# R7FA4W1AD register map
Vendor: Renesas; Series: RA4; File version: 1.0
CPU: CM4 r0p1, little endian, MPU, FPU, VTOR, 4 interrupt priority bits
Registers are 8-bit, read-write, reset 0x0 unless marked. A register's access mark holds for its fields unless they carry their own. Offsets are from the block's base; [hi:lo] are bit positions; {n}, {i} and the like mark numbered series.

## RTC — Realtime Clock
Base 0x40044000
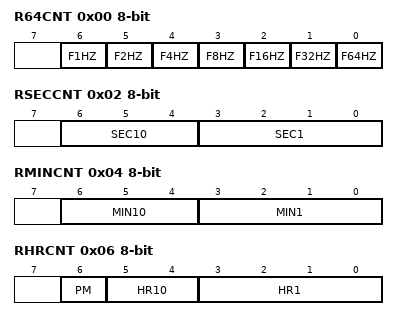
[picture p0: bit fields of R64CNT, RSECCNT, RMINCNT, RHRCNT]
0x00 R64CNT ro (reset mask 0x80) — 64-Hz Counter
  [6] F1HZ — 1Hz
  [5] F2HZ — 2Hz
  [4] F4HZ — 4Hz
  [3] F8HZ — 8Hz
  [2] F16HZ — 16Hz
  [1] F32HZ — 32Hz
  [0] F64HZ — 64Hz
0x02 RSECCNT reset not defined — Second Counter
  [6:4] SEC10 — 10-Second Count Counts from 0 to 5 for 60-second counting.
  [3:0] SEC1 — 1-Second Count Counts from 0 to 9 every second. When a carry is generated, 1 is added to the tens place.
0x02 BCNT0 reset not defined (alternate view of RSECCNT) — Binary Counter 0
  [7:0] BCNT0 — The BCNT0 counter is a readable/writable 32-bit binary counter b7 to b0.
0x04 RMINCNT reset not defined — Minute Counter
  [6:4] MIN10 — 10-Minute Count Counts from 0 to 5 for 60-minute counting.
  [3:0] MIN1 — 1-Minute Count Counts from 0 to 9 every minute. When a carry is generated, 1 is added to the tens place.
0x04 BCNT1 reset not defined (alternate view of RMINCNT) — Binary Counter 1
  [7:0] BCNT1 — The BCNT1 counter is a readable/writable 32-bit binary counter b15 to b8.
0x06 RHRCNT reset not defined — Hour Counter
  [6] PM — Time Counter Setting for a.m./p.m.
  [5:4] HR10 — 10-Hour Count Counts from 0 to 2 once per carry from the ones place.
  [3:0] HR1 — 1-Hour Count Counts from 0 to 9 once per hour. When a carry is generated, 1 is added to the tens place.
0x06 BCNT2 reset not defined (alternate view of RHRCNT) — Binary Counter 2
  [7:0] BCNT2 — The BCNT2 counter is a readable/writable 32-bit binary counter b23 to b16.
0x08 RWKCNT reset not defined — Day,of,Week Counter
  [2:0] DAYW — Day,of,Week Counting
0x08 BCNT3 reset not defined (alternate view of RWKCNT) — Binary Counter 3
  [7:0] BCNT3 — The BCNT3 counter is a readable/writable 32-bit binary counter b31 to b24.
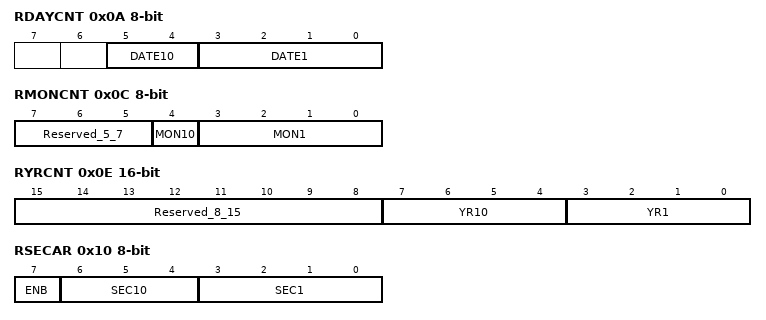
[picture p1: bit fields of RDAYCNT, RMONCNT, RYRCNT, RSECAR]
0x0A RDAYCNT (reset mask 0xC0) — Day Counter
  [5:4] DATE10 — 10-Day Count Counts from 0 to 3 once per carry from the ones place.
  [3:0] DATE1 — 1-Day Count Counts from 0 to 9 once per day. When a carry is generated, 1 is added to the tens place.
0x0C RMONCNT (reset mask 0xE0) — Month Counter
  [7:5] Reserved_5_7 — These bits are read as 000. The write value should be 000.
  [4] MON10 — 10-Month Count Counts from 0 to 1 once per carry from the ones place.
  [3:0] MON1 — 1-Month Count Counts from 0 to 9 once per month. When a carry is generated, 1 is added to the tens place.
0x0E RYRCNT 16-bit (reset mask 0xFF00) — Year Counter
  [15:8] Reserved_8_15 — These bits are read as 00000000. The write value should be 00000000.
  [7:4] YR10 — 10-Year Count Counts from 0 to 9 once per carry from ones place. When a carry is generated in the tens place, 1 is added to the hundreds place.
  [3:0] YR1 — 1-Year Count Counts from 0 to 9 once per year. When a carry is generated, 1 is added to the tens place.
0x10 RSECAR reset not defined — Second Alarm Register
  [7] ENB — Compare enable
  [6:4] SEC10 — 10-Seconds Value for the tens place of seconds
  [3:0] SEC1 wo — 1-Second Value for the ones place of seconds
0x10 BCNT0AR reset not defined (alternate view of RSECAR) — Binary Counter 0 Alarm Register
  [7:0] BCNT0AR — he BCNT0AR counter is a readable/writable alarm register corresponding to 32-bit binary counter b7 to b0.
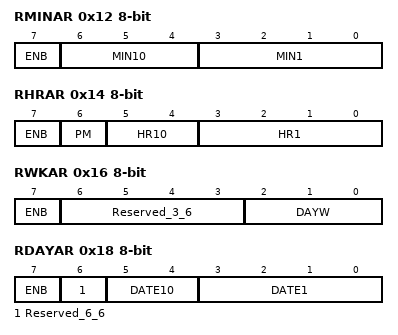
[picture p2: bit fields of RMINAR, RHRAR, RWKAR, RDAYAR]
0x12 RMINAR reset not defined — Minute Alarm Register
  [7] ENB — Compare enable
  [6:4] MIN10 — 10-Minute Count Value for the tens place of minutes
  [3:0] MIN1 — 1-Minute Count Value for the ones place of minutes
0x12 BCNT1AR reset not defined (alternate view of RMINAR) — Binary Counter 1 Alarm Register
  [7:0] BCNT1AR — he BCNT1AR counter is a readable/writable alarm register corresponding to 32-bit binary counter b15 to b8.
0x14 RHRAR reset not defined — Hour Alarm Register
  [7] ENB — Compare enable
  [6] PM — Time Counter Setting for a.m./p.m.
  [5:4] HR10 — 10-Hour Count Value for the tens place of hours
  [3:0] HR1 — 1-Hour Count Value for the ones place of hours
0x14 BCNT2AR reset not defined (alternate view of RHRAR) — Binary Counter 2 Alarm Register
  [7:0] BCNT2AR — The BCNT2AR counter is a readable/writable 32-bit binary counter b23 to b16.
0x16 RWKAR reset not defined — Day,of,Week Alarm Register
  [7] ENB — Compare enable
  [6:3] Reserved_3_6 — These bits are read as 0000. The write value should be 0000.
  [2:0] DAYW — Day,of,Week Counting
0x16 BCNT3AR reset not defined (alternate view of RWKAR) — Binary Counter 3 Alarm Register
  [7:0] BCNT3AR — The BCNT3AR counter is a readable/writable 32-bit binary counter b31 to b24.
0x18 RDAYAR reset not defined — Date Alarm Register
  [7] ENB — Compare enable
  [6] Reserved_6_6 — This bit is read as 0. The write value should be 0.
  [5:4] DATE10 — 10 Days Value for the tens place of days
  [3:0] DATE1 — 1 Day Value for the ones place of days
0x18 BCNT0AER reset not defined (alternate view of RDAYAR) — Binary Counter 0 Alarm Enable Register
  [7:0] ENB — The BCNT0AER register is a readable/writable register for setting the alarm enable corresponding to 32-bit binary counter b7 to b0.
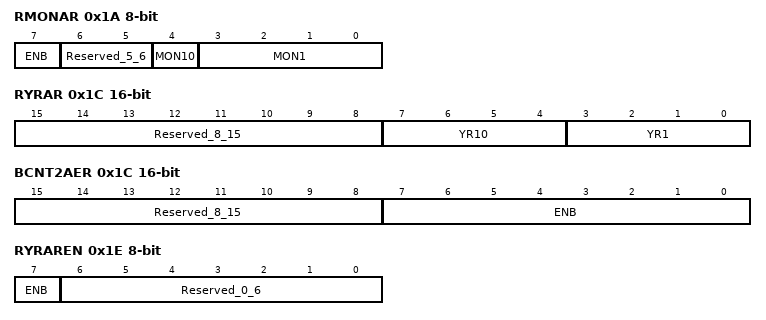
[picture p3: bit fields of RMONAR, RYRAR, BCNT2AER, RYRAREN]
0x1A RMONAR reset not defined — Month Alarm Register
  [7] ENB — Compare enable
  [6:5] Reserved_5_6 — These bits are read as 00. The write value should be 00.
  [4] MON10 — 10 Months Value for the tens place of months
  [3:0] MON1 — 1 Month Value for the ones place of months
0x1A BCNT1AER reset not defined (alternate view of RMONAR) — Binary Counter 1 Alarm Enable Register
  [7:0] ENB — The BCNT1AER register is a readable/writable register for setting the alarm enable corresponding to 32-bit binary counter b15 to b8.
0x1C RYRAR 16-bit (reset mask 0xFF00) — Year Alarm Register
  [15:8] Reserved_8_15 — These bits are read as 00000000. The write value should be 00000000.
  [7:4] YR10 — 10 Years Value for the tens place of years
  [3:0] YR1 — 1 Year Value for the ones place of years
0x1C BCNT2AER 16-bit (reset mask 0xFF00) (alternate view of RYRAR) — Binary Counter 2 Alarm Enable Register
  [15:8] Reserved_8_15 — These bits are read as 00000000. The write value should be 00000000.
  [7:0] ENB — The BCNT2AER register is a readable/writable register for setting the alarm enable corresponding to 32-bit binary counter b23 to b16.
0x1E RYRAREN reset not defined — Year Alarm Enable Register
  [7] ENB — Compare enable
  [6:0] Reserved_0_6 — These bits are read as 0000000. The write value should be 0000000.
0x1E BCNT3AER reset not defined (alternate view of RYRAREN) — Binary Counter 3 Alarm Enable Register
  [7:0] ENB — The BCNT3AER register is a readable/writable register for setting the alarm enable corresponding to 32-bit binary counter b31 to b24.
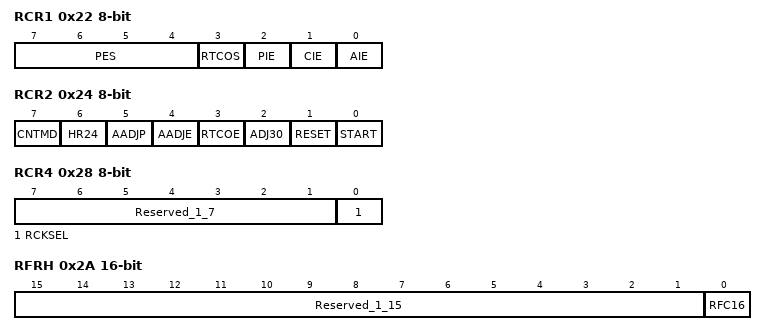
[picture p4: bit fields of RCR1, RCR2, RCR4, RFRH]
0x22 RCR1 (reset mask 0xA) — RTC Control Register 1
  [7:4] PES — Periodic Interrupt Select
  [3] RTCOS — RTCOUT Output Select
  [2] PIE — Periodic Interrupt Enable
  [1] CIE — Carry Interrupt Enable
  [0] AIE — Alarm Interrupt Enable
0x24 RCR2 (reset mask 0xE) — RTC Control Register 2
  [7] CNTMD — Count Mode Select
  [6] HR24 — Hours Mode
  [5] AADJP — Automatic Adjustment Period Select (When the LOCO clock is selected, the setting of this bit is disabled.)
  [4] AADJE — Automatic Adjustment Enable (When the LOCO clock is selected, the setting of this bit is disabled.)
  [3] RTCOE — RTCOUT Output Enable
  [2] ADJ30 — 30-Second Adjustment
  [1] RESET — RTC Software Reset
  [0] START
0x28 RCR4 (reset mask 0xFE) — RTC Control Register 4
  [7:1] Reserved_1_7 — These bits are read as 0000000. The write value should be 0000000.
  [0] RCKSEL — Count Source Select
0x2A RFRH 16-bit (reset mask 0xFFFE) — Frequency Register H
  [15:1] Reserved_1_15 — These bits are read as 000000000000000. The write value should be 000000000000000.
  [0] RFC16 — Frequency Comparison Value (b16) To generate the operating clock from the LOCOclock, this bit sets the comparison value of the 128-Hz clock cycle.
0x2C RFRL 16-bit reset not defined — Frequency Register L
  [15:0] RFC — Frequency Comparison Value(b15-b0) To generate the operating clock from the main clock, this bit sets the comparison value of the 128-Hz clock cycle.
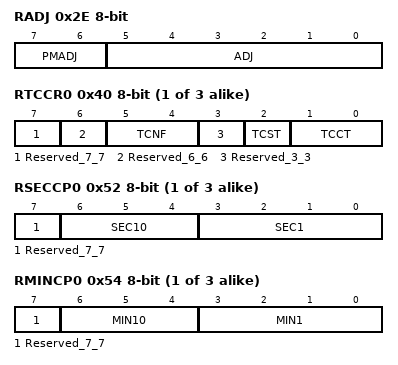
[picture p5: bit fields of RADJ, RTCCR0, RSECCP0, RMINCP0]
0x2E RADJ reset not defined — Time Error Adjustment Register
  [7:6] PMADJ — Plus,Minus
  [5:0] ADJ — Adjustment Value These bits specify the adjustment value from the prescaler.
{0x40+2i} RTCCR{i} (i=0..2) reset not defined — Time Capture Control Register {i}
  [7] Reserved_7_7 — This bit is read as 0. The write value should be 0.
  [6] Reserved_6_6 — This bit is read as 0. The write value should be 0.
  [5:4] TCNF — Time Capture Noise Filter Control
  [3] Reserved_3_3 — This bit is read as 0. The write value should be 0.
  [2] TCST ro — Time Capture Status
  [1:0] TCCT — Time Capture Control
{0x52+0x10*i} RSECCP{i} (i=0..2) ro reset not defined — Second Capture Register {i}
  [7] Reserved_7_7 — This bit is read as 0.
  [6:4] SEC10 — 10-Second Capture Capture value for the tens place of seconds
  [3:0] SEC1 — 1-Second Capture Capture value for the ones place of seconds
{0x52+0x10*i} BCNT0CP{i} (i=0..2) ro reset not defined (alternate view of RSECCP{i}) — BCNT0 Capture Register {i}
  [7:0] BCNT0CP — BCNT0CP is a read,only register that captures the BCNT0 value when a time capture event is detected.
{0x54+0x10*i} RMINCP{i} (i=0..2) ro reset not defined — Minute Capture Register {i}
  [7] Reserved_7_7 — This bit is read as 0.
  [6:4] MIN10 — 10-Minute Capture Capture value for the tens place of minutes
  [3:0] MIN1 — 1-Minute Capture Capture value for the ones place of minutes
{0x54+0x10*i} BCNT1CP{i} (i=0..2) ro reset not defined (alternate view of RMINCP{i}) — BCNT1 Capture Register {i}
  [7:0] BCNT1CP — BCNT1CP is a read,only register that captures the BCNT1 value when a time capture event is detected.
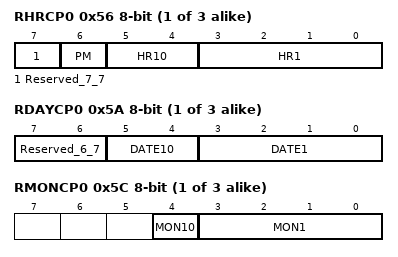
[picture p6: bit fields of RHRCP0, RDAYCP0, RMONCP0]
{0x56+0x10*i} RHRCP{i} (i=0..2) ro reset not defined — Hour Capture Register {i}
  [7] Reserved_7_7 — This bit is read as 0.
  [6] PM — A.m./p.m. select for time counter setting.
  [5:4] HR10 — 10-Minute Capture Capture value for the tens place of minutes
  [3:0] HR1 — 1-Minute Capture Capture value for the ones place of minutes
{0x56+0x10*i} BCNT2CP{i} (i=0..2) ro reset not defined (alternate view of RHRCP{i}) — BCNT2 Capture Register {i}
  [7:0] BCNT2CP — BCNT2CP is a read,only register that captures the BCNT2 value when a time capture event is detected.
{0x5A+0x10*i} RDAYCP{i} (i=0..2) ro reset not defined — Date Capture Register {i}
  [7:6] Reserved_6_7 — These bits are read as 00.
  [5:4] DATE10 — 10-Day Capture Capture value for the tens place of minutes
  [3:0] DATE1 — 1-Day Capture Capture value for the ones place of minutes
{0x5A+0x10*i} BCNT3CP{i} (i=0..2) ro reset not defined (alternate view of RDAYCP{i}) — BCNT3 Capture Register {i}
  [7:0] BCNT3CP — BCNT3CP is a read,only register that captures the BCNT3 value when a time capture event is detected.
{0x5C+0x10*i} RMONCP{i} (i=0..2) ro reset not defined — Month Capture Register {i}
  [4] MON10 — 10-Month Capture Capture value for the tens place of months
  [3:0] MON1 — 1-Month Capture Capture value for the ones place of months
